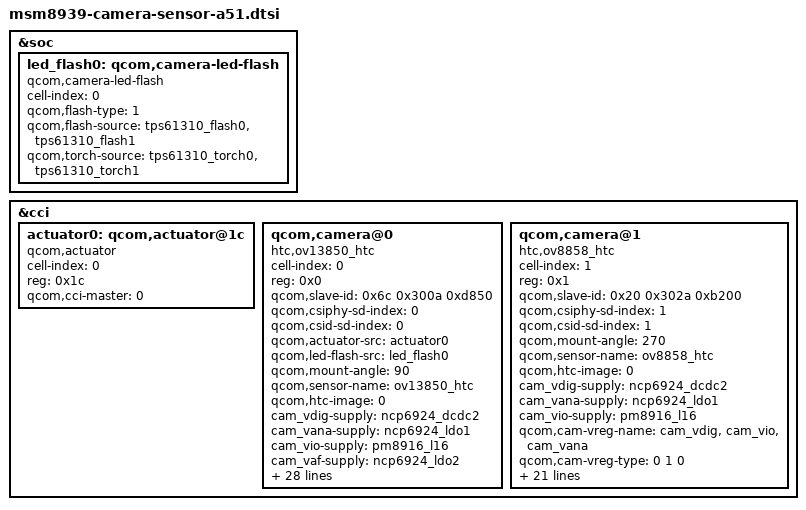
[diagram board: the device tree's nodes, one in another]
/*
 * Copyright (c) 2014, The Linux Foundation. All rights reserved.
 *
 * This program is free software; you can redistribute it and/or modify
 * it under the terms of the GNU General Public License version 2 and
 * only version 2 as published by the Free Software Foundation.
 *
 * This program is distributed in the hope that it will be useful,
 * but WITHOUT ANY WARRANTY; without even the implied warranty of
 * MERCHANTABILITY or FITNESS FOR A PARTICULAR PURPOSE.  See the
 * GNU General Public License for more details.
 */

&soc {

	led_flash0: qcom,camera-led-flash {
		cell-index = <0>;
		compatible = "qcom,camera-led-flash";
		qcom,flash-type = <1>;
		qcom,flash-source = <&tps61310_flash0 &tps61310_flash1>;
		qcom,torch-source = <&tps61310_torch0 &tps61310_torch1>;
	};
};

&cci {

	actuator0: qcom,actuator@1c {
		cell-index = <0>;
		reg = <0x1c>;
		compatible = "qcom,actuator";
		qcom,cci-master = <0>;
	};

	qcom,camera@0 {
		cell-index = <0>;
		compatible = "htc,ov13850_htc";
		reg = <0x0>;
		qcom,slave-id = <0x6c 0x300a 0xd850>;
		qcom,csiphy-sd-index = <0>;
		qcom,csid-sd-index = <0>;
		qcom,actuator-src = <&actuator0>;
		qcom,led-flash-src = <&led_flash0>;
		qcom,mount-angle = <90>;
		qcom,sensor-name = "ov13850_htc";
		qcom,htc-image = <0>;
		cam_vdig-supply = <&ncp6924_dcdc2>;
		cam_vana-supply = <&ncp6924_ldo1>;
		cam_vio-supply = <&pm8916_l16>;
		cam_vaf-supply = <&ncp6924_ldo2>;
		qcom,cam-vreg-name = "cam_vdig", "cam_vio", "cam_vana", "cam_vaf";
		qcom,cam-vreg-type = <0 1 0 0>;
		qcom,cam-vreg-min-voltage = <1200000 0 2800000 2800000>;
		qcom,cam-vreg-max-voltage = <1200000 0 2800000 2800000>;
		qcom,cam-vreg-op-mode = <0 0 0 0>;
		qcom,cam-vreg-gpios-index = <99 99 99 99>;
		qcom,gpio-no-mux = <0>;
		pinctrl-names = "cam_default", "cam_suspend";
		pinctrl-0 = <&cam_sensor_mclk0_default
				&cam_sensor_rear_default>;
		pinctrl-1 = <&cam_sensor_mclk0_sleep &cam_sensor_rear_sleep>;
		gpios = <&msm_gpio 26 0>,
				<&msm_gpio 35 0>,
				<&msm_gpio 50 0>;
		qcom,gpio-reset = <1>;
		qcom,gpio-vcm-pwd = <2>;
		qcom,gpio-req-tbl-num = <0 1 2>;
		qcom,gpio-req-tbl-flags = <1 0 0>;
		qcom,gpio-req-tbl-label = "MCLK_CPU",
					              "CAM_RST",
					              "CAM_VCM_PD";

		qcom,csi-lane-assign = <0x4320>;
		qcom,csi-lane-mask = <0x1F>;
		qcom,sensor-position = <0>;
		qcom,sensor-mode = <0>;
		qcom,cci-master = <0>;
		status = "ok";
		clocks = <&clock_gcc clk_mclk0_clk_src>,
				<&clock_gcc clk_gcc_camss_mclk0_clk>;
		clock-names = "cam_src_clk", "cam_clk";
	};

	qcom,camera@1 {
		cell-index = <1>;
		compatible = "htc,ov8858_htc";
		reg = <0x1>;
		qcom,slave-id = <0x20 0x302a 0xb200>;
		qcom,csiphy-sd-index = <1>;
		qcom,csid-sd-index = <1>;
		qcom,mount-angle = <270>;
		qcom,sensor-name = "ov8858_htc";
		qcom,htc-image = <0>;
		cam_vdig-supply = <&ncp6924_dcdc2>;
		cam_vana-supply = <&ncp6924_ldo1>;
		cam_vio-supply = <&pm8916_l16>;
		qcom,cam-vreg-name = "cam_vdig", "cam_vio", "cam_vana";
		qcom,cam-vreg-type = <0 1 0>;
		qcom,cam-vreg-min-voltage = <1200000 0 2800000>;
		qcom,cam-vreg-max-voltage = <1200000 0 2800000>;
		qcom,cam-vreg-op-mode = <0 0 0>;
		qcom,cam-vreg-gpios-index = <99 99 99>;
		qcom,gpio-no-mux = <0>;
		pinctrl-names = "cam_default", "cam_suspend";
		pinctrl-0 = <&cam_sensor_mclk1_default
				&cam_sensor_front_default>;
		pinctrl-1 = <&cam_sensor_mclk1_sleep &cam_sensor_front_sleep>;
		gpios = <&msm_gpio 27 0>,
				<&msm_gpio 28 0>;
		qcom,gpio-reset = <1>;
		qcom,gpio-req-tbl-num = <0 1>;
		qcom,gpio-req-tbl-flags = <1 0>;
		qcom,gpio-req-tbl-label = "MCLK_CPU",
						"CAM_RST";

		qcom,csi-lane-assign = <0x4320>;
		qcom,csi-lane-mask = <0x1F>;
		qcom,sensor-position = <1>;
		qcom,sensor-mode = <1>;
		qcom,cci-master = <0>;
		status = "ok";
		clocks = <&clock_gcc clk_mclk1_clk_src>,
				<&clock_gcc clk_gcc_camss_mclk1_clk>;
		clock-names = "cam_src_clk", "cam_clk";
	};

};
